# Espressif register map
File version: 1.0
CPU: Xtensa LX6 1, little endian, no MPU, FPU, 3 interrupt priority bits
Registers are 32-bit, access not given, reset 0x0 unless marked. A register's access mark holds for its fields unless they carry their own. Offsets are from the block's base; [hi:lo] are bit positions; {n}, {i} and the like mark numbered series; 'fields as' and 'values as' point back to an identical list.

## TIMG
Base 0x00000000
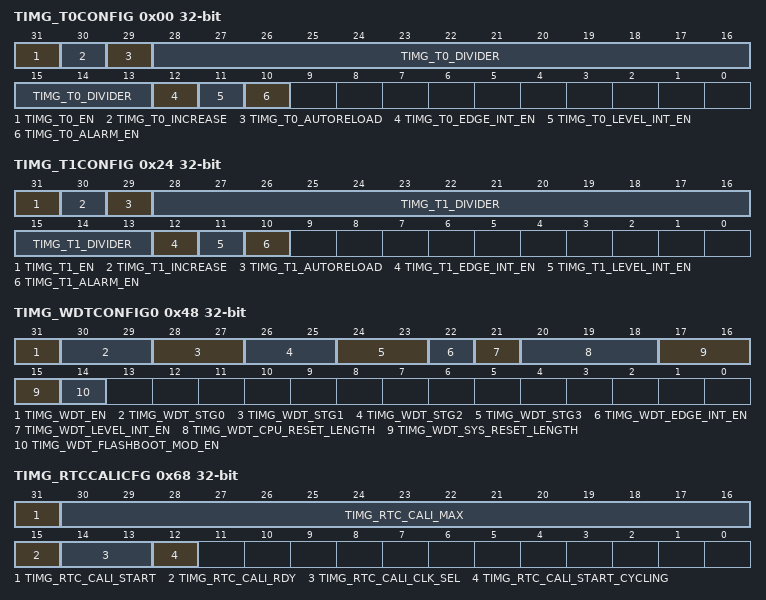
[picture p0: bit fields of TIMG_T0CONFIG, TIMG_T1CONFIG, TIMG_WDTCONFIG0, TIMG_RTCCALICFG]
0x00 TIMG_T0CONFIG
  [31] TIMG_T0_EN, [30] TIMG_T0_INCREASE, [29] TIMG_T0_AUTORELOAD, [28:13] TIMG_T0_DIVIDER, [12] TIMG_T0_EDGE_INT_EN, [11] TIMG_T0_LEVEL_INT_EN, [10] TIMG_T0_ALARM_EN
0x04 TIMG_T0LO
  [31:0] TIMG_T0_LO
0x08 TIMG_T0HI
  [31:0] TIMG_T0_HI
0x0C TIMG_T0UPDATE
  [31:0] TIMG_T0_UPDATE
0x10 TIMG_T0ALARMLO
  [31:0] TIMG_T0_ALARM_LO
0x14 TIMG_T0ALARMHI
  [31:0] TIMG_T0_ALARM_HI
0x18 TIMG_T0LOADLO
  [31:0] TIMG_T0_LOAD_LO
0x1C TIMG_T0LOADHI
  [31:0] TIMG_T0_LOAD_HI
0x20 TIMG_T0LOAD
  [31:0] TIMG_T0_LOAD
0x24 TIMG_T1CONFIG
  [31] TIMG_T1_EN, [30] TIMG_T1_INCREASE, [29] TIMG_T1_AUTORELOAD, [28:13] TIMG_T1_DIVIDER, [12] TIMG_T1_EDGE_INT_EN, [11] TIMG_T1_LEVEL_INT_EN, [10] TIMG_T1_ALARM_EN
0x28 TIMG_T1LO
  [31:0] TIMG_T1_LO
0x2C TIMG_T1HI
  [31:0] TIMG_T1_HI
0x30 TIMG_T1UPDATE
  [31:0] TIMG_T1_UPDATE
0x34 TIMG_T1ALARMLO
  [31:0] TIMG_T1_ALARM_LO
0x38 TIMG_T1ALARMHI
  [31:0] TIMG_T1_ALARM_HI
0x3C TIMG_T1LOADLO
  [31:0] TIMG_T1_LOAD_LO
0x40 TIMG_T1LOADHI
  [31:0] TIMG_T1_LOAD_HI
0x44 TIMG_T1LOAD
  [31:0] TIMG_T1_LOAD
0x48 TIMG_WDTCONFIG0
  [31] TIMG_WDT_EN, [30-2n:29-2n] TIMG_WDT_STG{n} (n=0..3), [22] TIMG_WDT_EDGE_INT_EN, [21] TIMG_WDT_LEVEL_INT_EN, [20:18] TIMG_WDT_CPU_RESET_LENGTH, [17:15] TIMG_WDT_SYS_RESET_LENGTH, [14] TIMG_WDT_FLASHBOOT_MOD_EN
0x4C TIMG_WDTCONFIG1
  [31:16] TIMG_WDT_CLK_PRESCALE
{0x48+4i} TIMG_WDTCONFIG{i} (i=2..5)
  [31:0] TIMG_WDT_STG{i-2}_HOLD
0x60 TIMG_WDTFEED
  [31:0] TIMG_WDT_FEED
0x64 TIMG_WDTWPROTECT
  [31:0] TIMG_WDT_WKEY
0x68 TIMG_RTCCALICFG
  [31] TIMG_RTC_CALI_START, [30:16] TIMG_RTC_CALI_MAX, [15] TIMG_RTC_CALI_RDY, [14:13] TIMG_RTC_CALI_CLK_SEL, [12] TIMG_RTC_CALI_START_CYCLING
0x6C TIMG_RTCCALICFG1
  [31:7] TIMG_RTC_CALI_VALUE
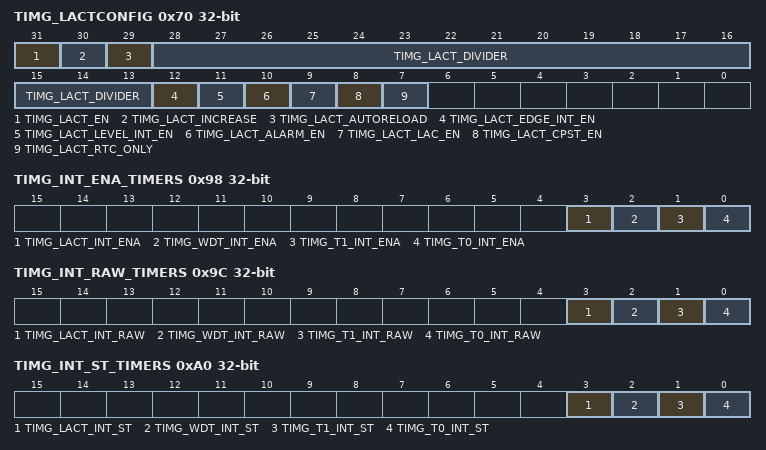
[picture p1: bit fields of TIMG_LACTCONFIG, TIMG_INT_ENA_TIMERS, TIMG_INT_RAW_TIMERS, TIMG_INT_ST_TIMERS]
0x70 TIMG_LACTCONFIG
  [31] TIMG_LACT_EN, [30] TIMG_LACT_INCREASE, [29] TIMG_LACT_AUTORELOAD, [28:13] TIMG_LACT_DIVIDER, [12] TIMG_LACT_EDGE_INT_EN, [11] TIMG_LACT_LEVEL_INT_EN, [10] TIMG_LACT_ALARM_EN, [9] TIMG_LACT_LAC_EN, [8] TIMG_LACT_CPST_EN, [7] TIMG_LACT_RTC_ONLY
0x74 TIMG_LACTRTC
  [31:6] TIMG_LACT_RTC_STEP_LEN
0x78 TIMG_LACTLO
  [31:0] TIMG_LACT_LO
0x7C TIMG_LACTHI
  [31:0] TIMG_LACT_HI
0x80 TIMG_LACTUPDATE
  [31:0] TIMG_LACT_UPDATE
0x84 TIMG_LACTALARMLO
  [31:0] TIMG_LACT_ALARM_LO
0x88 TIMG_LACTALARMHI
  [31:0] TIMG_LACT_ALARM_HI
0x8C TIMG_LACTLOADLO
  [31:0] TIMG_LACT_LOAD_LO
0x90 TIMG_LACTLOADHI
  [31:0] TIMG_LACT_LOAD_HI
0x94 TIMG_LACTLOAD
  [31:0] TIMG_LACT_LOAD
0x98 TIMG_INT_ENA_TIMERS
  [3] TIMG_LACT_INT_ENA, [2] TIMG_WDT_INT_ENA, [1] TIMG_T1_INT_ENA, [0] TIMG_T0_INT_ENA
0x9C TIMG_INT_RAW_TIMERS
  [3] TIMG_LACT_INT_RAW, [2] TIMG_WDT_INT_RAW, [1] TIMG_T1_INT_RAW, [0] TIMG_T0_INT_RAW
0xA0 TIMG_INT_ST_TIMERS
  [3] TIMG_LACT_INT_ST, [2] TIMG_WDT_INT_ST, [1] TIMG_T1_INT_ST, [0] TIMG_T0_INT_ST
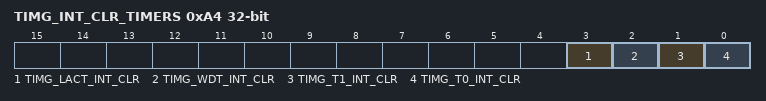
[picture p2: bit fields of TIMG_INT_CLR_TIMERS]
0xA4 TIMG_INT_CLR_TIMERS
  [3] TIMG_LACT_INT_CLR, [2] TIMG_WDT_INT_CLR, [1] TIMG_T1_INT_CLR, [0] TIMG_T0_INT_CLR
0xF8 TIMG_NTIMERS_DATE
  [27:0] TIMG_NTIMERS_DATE
0xFC TIMGCLK
  [31] TIMG_CLK_EN

## GPIO_SD
Base 0x3FF44F00
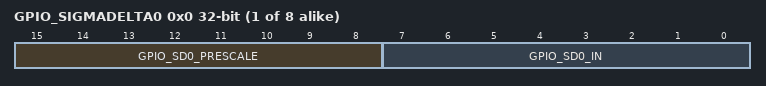
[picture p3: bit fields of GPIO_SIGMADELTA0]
{0x0+4i} GPIO_SIGMADELTA{i} (i=0..7)
  [15:8] GPIO_SD{i}_PRESCALE, [7:0] GPIO_SD{i}_IN
0x20 GPIO_SIGMADELTA_CG
  [31] GPIO_SD_CLK_EN
0x24 GPIO_SIGMADELTA_MISC
  [31] GPIO_SPI_SWAP
0x28 GPIO_SIGMADELTA_VERSION
  [27:0] GPIO_SD_DATE

## IO_MUX
Base 0x3FF49000
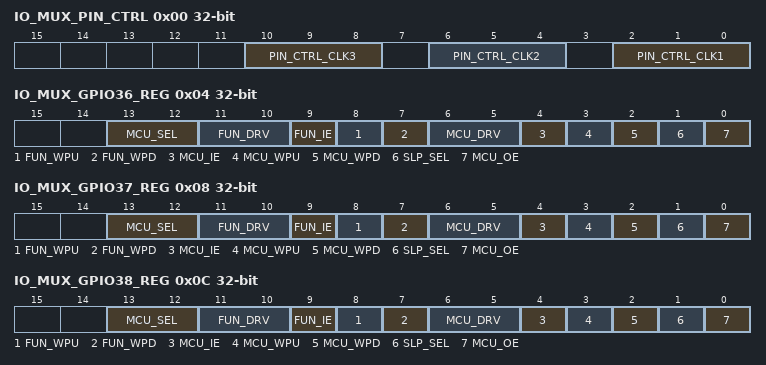
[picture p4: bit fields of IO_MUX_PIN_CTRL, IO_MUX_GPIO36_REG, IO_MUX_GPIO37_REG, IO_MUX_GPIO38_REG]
0x00 IO_MUX_PIN_CTRL
  [10:8] PIN_CTRL_CLK3, [6:4] PIN_CTRL_CLK2, [2:0] PIN_CTRL_CLK1
0x04 IO_MUX_GPIO36_REG
  [13:12] MCU_SEL, [11:10] FUN_DRV, [9] FUN_IE, [8] FUN_WPU, [7] FUN_WPD, [6:5] MCU_DRV, [4] MCU_IE, [3] MCU_WPU, [2] MCU_WPD, [1] SLP_SEL, [0] MCU_OE
0x08 IO_MUX_GPIO37_REG
  fields as IO_MUX_GPIO36_REG
0x0C IO_MUX_GPIO38_REG
  fields as IO_MUX_GPIO36_REG
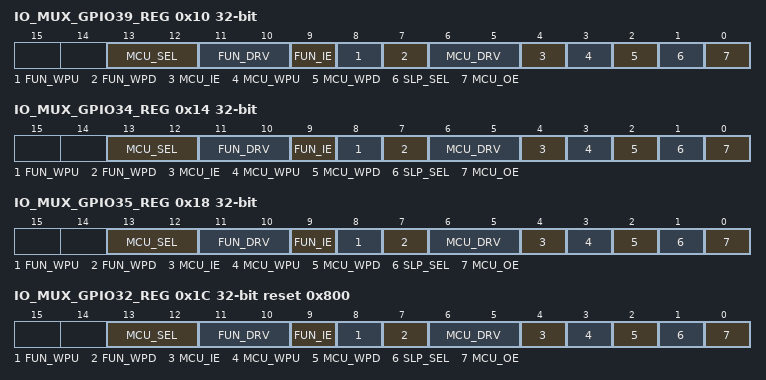
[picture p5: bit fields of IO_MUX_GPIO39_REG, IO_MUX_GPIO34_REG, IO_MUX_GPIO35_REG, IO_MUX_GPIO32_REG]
0x10 IO_MUX_GPIO39_REG
  fields as IO_MUX_GPIO36_REG
0x14 IO_MUX_GPIO34_REG
  fields as IO_MUX_GPIO36_REG
0x18 IO_MUX_GPIO35_REG
  fields as IO_MUX_GPIO36_REG
0x1C IO_MUX_GPIO32_REG reset 0x800
  fields as IO_MUX_GPIO36_REG
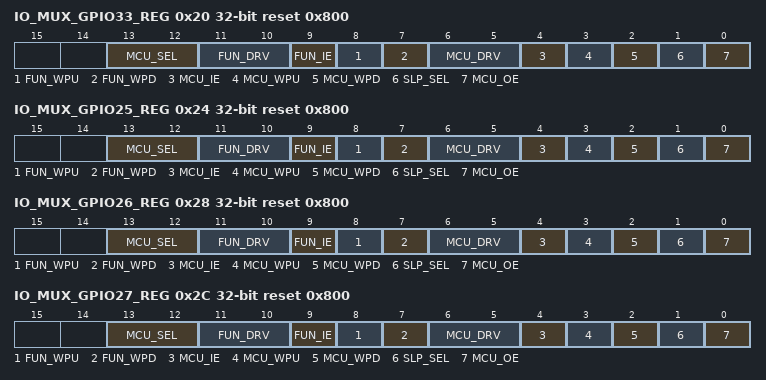
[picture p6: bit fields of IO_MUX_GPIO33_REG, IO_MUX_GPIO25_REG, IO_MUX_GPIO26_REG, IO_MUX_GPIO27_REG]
0x20 IO_MUX_GPIO33_REG reset 0x800
  fields as IO_MUX_GPIO36_REG
0x24 IO_MUX_GPIO25_REG reset 0x800
  fields as IO_MUX_GPIO36_REG
0x28 IO_MUX_GPIO26_REG reset 0x800
  fields as IO_MUX_GPIO36_REG
0x2C IO_MUX_GPIO27_REG reset 0x800
  fields as IO_MUX_GPIO36_REG
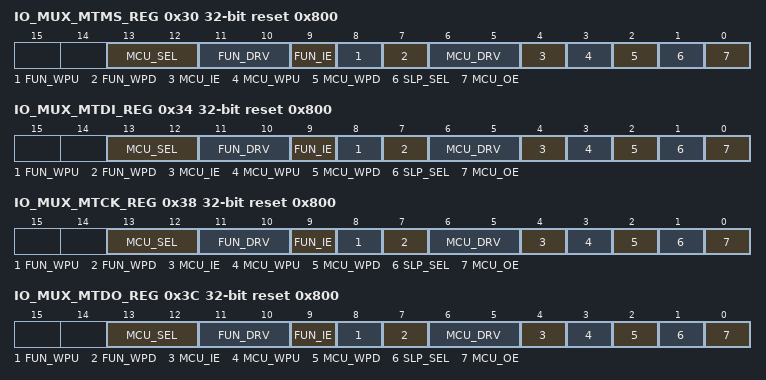
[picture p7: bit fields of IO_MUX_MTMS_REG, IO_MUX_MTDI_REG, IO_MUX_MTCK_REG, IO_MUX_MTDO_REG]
0x30 IO_MUX_MTMS_REG reset 0x800
  fields as IO_MUX_GPIO36_REG
0x34 IO_MUX_MTDI_REG reset 0x800
  fields as IO_MUX_GPIO36_REG
0x38 IO_MUX_MTCK_REG reset 0x800
  fields as IO_MUX_GPIO36_REG
0x3C IO_MUX_MTDO_REG reset 0x800
  fields as IO_MUX_GPIO36_REG
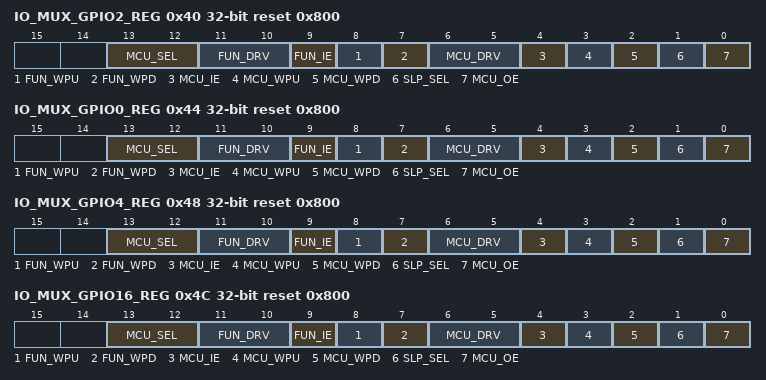
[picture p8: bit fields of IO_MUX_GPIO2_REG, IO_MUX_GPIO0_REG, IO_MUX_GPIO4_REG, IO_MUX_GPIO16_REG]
0x40 IO_MUX_GPIO2_REG reset 0x800
  fields as IO_MUX_GPIO36_REG
0x44 IO_MUX_GPIO0_REG reset 0x800
  fields as IO_MUX_GPIO36_REG
0x48 IO_MUX_GPIO4_REG reset 0x800
  fields as IO_MUX_GPIO36_REG
0x4C IO_MUX_GPIO16_REG reset 0x800
  fields as IO_MUX_GPIO36_REG
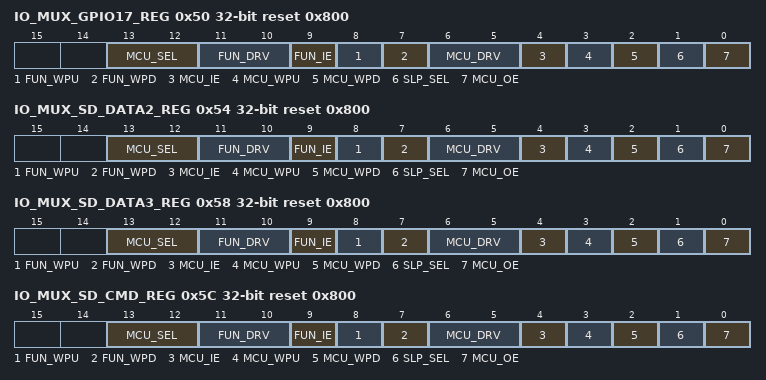
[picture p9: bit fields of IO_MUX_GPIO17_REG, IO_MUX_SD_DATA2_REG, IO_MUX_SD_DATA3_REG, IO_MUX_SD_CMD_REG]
0x50 IO_MUX_GPIO17_REG reset 0x800
  fields as IO_MUX_GPIO36_REG
0x54 IO_MUX_SD_DATA2_REG reset 0x800
  fields as IO_MUX_GPIO36_REG
0x58 IO_MUX_SD_DATA3_REG reset 0x800
  fields as IO_MUX_GPIO36_REG
0x5C IO_MUX_SD_CMD_REG reset 0x800
  fields as IO_MUX_GPIO36_REG
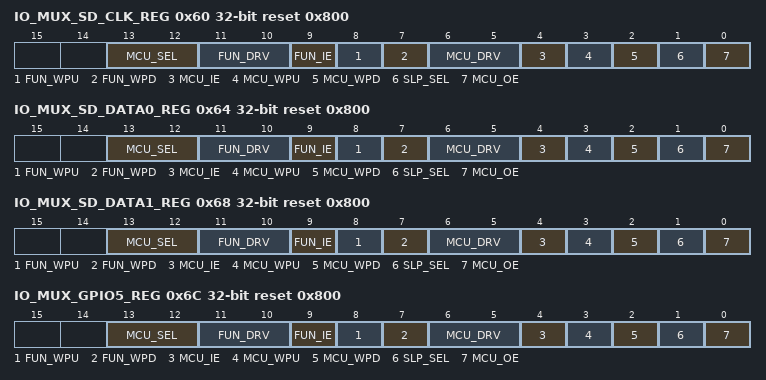
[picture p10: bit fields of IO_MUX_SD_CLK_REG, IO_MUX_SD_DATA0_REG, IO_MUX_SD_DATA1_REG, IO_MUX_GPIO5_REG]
0x60 IO_MUX_SD_CLK_REG reset 0x800
  fields as IO_MUX_GPIO36_REG
0x64 IO_MUX_SD_DATA0_REG reset 0x800
  fields as IO_MUX_GPIO36_REG
0x68 IO_MUX_SD_DATA1_REG reset 0x800
  fields as IO_MUX_GPIO36_REG
0x6C IO_MUX_GPIO5_REG reset 0x800
  fields as IO_MUX_GPIO36_REG
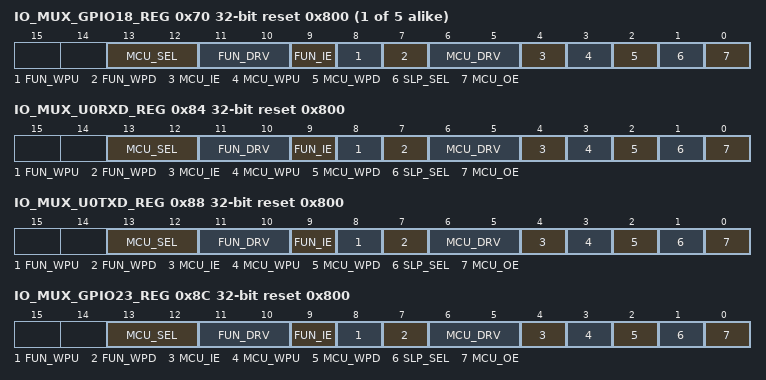
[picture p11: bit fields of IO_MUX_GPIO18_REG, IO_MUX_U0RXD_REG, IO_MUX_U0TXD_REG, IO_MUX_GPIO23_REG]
{0x28+4i} IO_MUX_GPIO{i}_REG reset 0x800 (i=18..22)
  fields as IO_MUX_GPIO36_REG
0x84 IO_MUX_U0RXD_REG reset 0x800
  fields as IO_MUX_GPIO36_REG
0x88 IO_MUX_U0TXD_REG reset 0x800
  fields as IO_MUX_GPIO36_REG
0x8C IO_MUX_GPIO23_REG reset 0x800
  fields as IO_MUX_GPIO36_REG
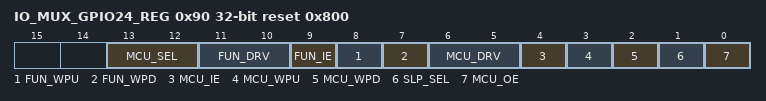
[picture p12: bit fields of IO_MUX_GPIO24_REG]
0x90 IO_MUX_GPIO24_REG reset 0x800
  fields as IO_MUX_GPIO36_REG
